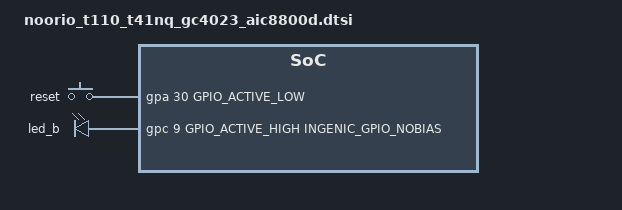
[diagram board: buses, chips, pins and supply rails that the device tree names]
// Noorio T110 (T41NQ, GC4023, AIC8800 USB) per-board nodes for the
// 4.4.94 device tree; ignored on 3.10 kernels.
// Pins: PB26 SD card detect, PA30 reset button (active-low),
// PC9 blue status LED. SD power PB29 is runtime-side via
// gpio.mmc_power (thingino.json -> S09mmc), not in the DT.

#include <dt-bindings/gpio/gpio.h>
#include <dt-bindings/input/input.h>
#include <dt-bindings/pinctrl/ingenic-pinctrl.h>

/* PB26 card detect: stock DTB pairs cd-gpios with cd-inverted, and the
 * vendor sdhci only switches to GPIO detection when cd-inverted is
 * present -- keep both lines. */
&msc0 {
	ingenic,cd-gpios = <&gpb 26 GPIO_ACTIVE_LOW INGENIC_GPIO_NOBIAS>;
	cd-inverted;
};

/ {
	gpio-keys {
		compatible = "gpio-keys";
		label = "gpio-keys";

		reset {
			label = "reset";
			linux,code = <KEY_ENTER>;
			gpios = <&gpa 30 GPIO_ACTIVE_LOW INGENIC_GPIO_PULLUP>;
		};
	};

	gpio-leds {
		compatible = "gpio-leds";

		led_b {
			label = "led_b";
			gpios = <&gpc 9 GPIO_ACTIVE_HIGH INGENIC_GPIO_NOBIAS>;
			default-state = "off";
		};
	};
};
